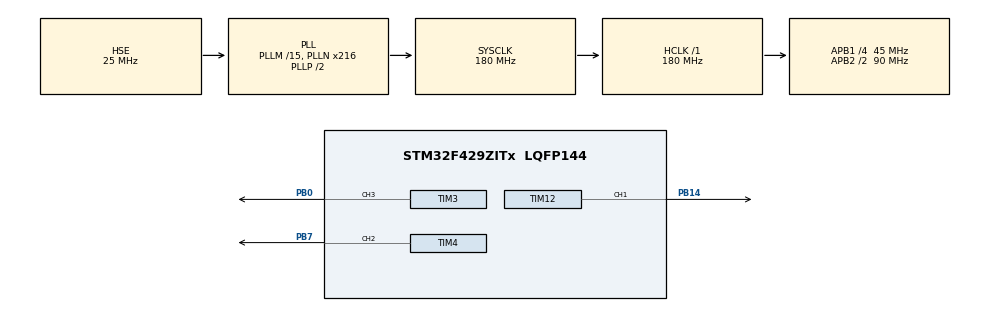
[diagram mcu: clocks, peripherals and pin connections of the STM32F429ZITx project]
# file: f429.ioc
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Mcu.Family=STM32F4
Mcu.Name=STM32F429ZITx
Mcu.Package=LQFP144
NVIC.PriorityGroup=NVIC_PRIORITYGROUP_4
NVIC.TIM4_IRQn=true\:0\:0\:false\:false\:true\:true\:true\:true
NVIC.TIM8_BRK_TIM12_IRQn=true\:0\:0\:false\:false\:true\:true\:true\:true
PA13.Mode=Serial_Wire
PA13.Signal=SYS_JTMS-SWDIO
PA14.Mode=Serial_Wire
PA14.Signal=SYS_JTCK-SWCLK
PB0.Signal=S_TIM3_CH3
PB14.Signal=S_TIM12_CH1
PB7.Signal=S_TIM4_CH2
PH0/OSC_IN.Mode=HSE-External-Oscillator
PH0/OSC_IN.Signal=RCC_OSC_IN
PH1/OSC_OUT.Mode=HSE-External-Oscillator
PH1/OSC_OUT.Signal=RCC_OSC_OUT
ProjectManager.HeapSize=0x200
ProjectManager.StackSize=0x400
ProjectManager.TargetToolchain=STM32CubeIDE
RCC.48MHZClocksFreq_Value=90000000
RCC.AHBFreq_Value=180000000
RCC.APB1CLKDivider=RCC_HCLK_DIV4
RCC.APB1Freq_Value=45000000
RCC.APB1TimFreq_Value=90000000
RCC.APB2CLKDivider=RCC_HCLK_DIV2
RCC.APB2Freq_Value=90000000
RCC.APB2TimFreq_Value=180000000
RCC.CortexFreq_Value=180000000
RCC.HCLKFreq_Value=180000000
RCC.HSE_VALUE=25000000
RCC.HSI_VALUE=16000000
RCC.LSE_VALUE=32768
RCC.PLLM=15
RCC.PLLN=216
RCC.PLLSourceVirtual=RCC_PLLSOURCE_HSE
RCC.SYSCLKFreq_VALUE=180000000
RCC.SYSCLKSource=RCC_SYSCLKSOURCE_PLLCLK
RCC.VCOOutputFreq_Value=360000000
SH.S_TIM12_CH1.0=TIM12_CH1,PWM Generation1 CH1
SH.S_TIM3_CH3.0=TIM3_CH3,PWM Generation3 CH3
SH.S_TIM4_CH2.0=TIM4_CH2,PWM Generation2 CH2
TIM12.Channel-PWM\ Generation1\ CH1=TIM_CHANNEL_1
TIM12.Period=60000
TIM12.Pulse-PWM\ Generation1\ CH1=30000
TIM3.Channel-PWM\ Generation3\ CH3=TIM_CHANNEL_3
TIM3.Period=60000
TIM3.Pulse-PWM\ Generation3\ CH3=30000
TIM4.Channel-PWM\ Generation2\ CH2=TIM_CHANNEL_2
TIM4.Period=60000
TIM4.Pulse-PWM\ Generation2\ CH2=30000
board=custom

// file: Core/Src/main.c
/* USER CODE BEGIN Header */
/**
  ******************************************************************************
  * @file           : main.c
  * @brief          : Main program body
  ******************************************************************************
  * @attention
  *
  * Copyright (c) 2022 STMicroelectronics.
  * All rights reserved.
  *
  * This software is licensed under terms that can be found in the LICENSE file
  * in the root directory of this software component.
  * If no LICENSE file comes with this software, it is provided AS-IS.
  *
  ******************************************************************************
  */
/* USER CODE END Header */
#include "main.h"

 TIM_HandleTypeDef htim3;
TIM_HandleTypeDef htim4;
TIM_HandleTypeDef htim12;

void SystemClock_Config(void);
static void MX_GPIO_Init(void);
static void MX_TIM4_Init(void);
static void MX_TIM12_Init(void);
static void MX_TIM3_Init(void);

int main(void)
{

  /* MCU Configuration--------------------------------------------------------*/

  /* Reset of all peripherals, Initializes the Flash interface and the Systick. */
  HAL_Init();

  /* Configure the system clock */
  SystemClock_Config();

  /* Initialize all configured peripherals */
  MX_GPIO_Init();
  MX_TIM4_Init();
  MX_TIM12_Init();
  MX_TIM3_Init();
  /* USER CODE BEGIN 2 */
  HAL_TIM_PWM_Start_IT(&htim4, TIM_CHANNEL_2);
  HAL_TIM_PWM_Start_IT(&htim12, TIM_CHANNEL_1);
  HAL_TIM_PWM_Start_IT(&htim3, TIM_CHANNEL_3);
  uint16_t i = 0;
    volatile uint16_t j = 0;

  /* USER CODE END 2 */

  /* Infinite loop */
  /* USER CODE BEGIN WHILE */
  while (1)
  {
	  for(i = 0; i <= 60000; i++)
	            {
		  __HAL_TIM_SET_COMPARE(&htim4, TIM_CHANNEL_2, i);
	                    for(j = 0; j < 100; j++) __NOP();
	            }

	            HAL_Delay(200);

	            for(i = 60000; i > 0; i--)
	            {
	            	__HAL_TIM_SET_COMPARE(&htim4, TIM_CHANNEL_2, i);
	                    for(j = 0; j < 100; j++) __NOP();
	            }

	            HAL_Delay(200);

	            for(i = 0; i <= 60000; i++)
	            	            {
	            		  __HAL_TIM_SET_COMPARE(&htim12, TIM_CHANNEL_1, i);
	            	                    for(j = 0; j < 100; j++) __NOP();
	            	            }

	            	            HAL_Delay(200);

	            	            for(i = 60000; i > 0; i--)
	            	            {
	            	            	__HAL_TIM_SET_COMPARE(&htim12, TIM_CHANNEL_1, i);
	            	                    for(j = 0; j < 100; j++) __NOP();
	            	            }

	            	            HAL_Delay(200);

	            	            for(i = 0; i <= 60000; i++)
	            	            	            {
	            	            		  __HAL_TIM_SET_COMPARE(&htim3, TIM_CHANNEL_3, i);
	            	            	                    for(j = 0; j < 100; j++) __NOP();
	            	            	            }

	            	            	            HAL_Delay(200);

	            	            	            for(i = 60000; i > 0; i--)
	            	            	            {
	            	            	            	__HAL_TIM_SET_COMPARE(&htim3, TIM_CHANNEL_3, i);
	            	            	                    for(j = 0; j < 100; j++) __NOP();
	            	            	            }

	            	            	            HAL_Delay(200);

    /* USER CODE END WHILE */

  }
}

void SystemClock_Config(void)
{
  RCC_OscInitTypeDef RCC_OscInitStruct = {0};
  RCC_ClkInitTypeDef RCC_ClkInitStruct = {0};

  /** Configure the main internal regulator output voltage
  */
  __HAL_RCC_PWR_CLK_ENABLE();
  __HAL_PWR_VOLTAGESCALING_CONFIG(PWR_REGULATOR_VOLTAGE_SCALE1);

  /** Initializes the RCC Oscillators according to the specified parameters
  * in the RCC_OscInitTypeDef structure.
  */
  RCC_OscInitStruct.OscillatorType = RCC_OSCILLATORTYPE_HSE;
  RCC_OscInitStruct.HSEState = RCC_HSE_ON;
  RCC_OscInitStruct.PLL.PLLState = RCC_PLL_ON;
  RCC_OscInitStruct.PLL.PLLSource = RCC_PLLSOURCE_HSE;
  RCC_OscInitStruct.PLL.PLLM = 15;
  RCC_OscInitStruct.PLL.PLLN = 216;
  RCC_OscInitStruct.PLL.PLLP = RCC_PLLP_DIV2;
  RCC_OscInitStruct.PLL.PLLQ = 4;
  if (HAL_RCC_OscConfig(&RCC_OscInitStruct) != HAL_OK)
  {
    Error_Handler();
  }

  /** Activate the Over-Drive mode
  */
  if (HAL_PWREx_EnableOverDrive() != HAL_OK)
  {
    Error_Handler();
  }

  /** Initializes the CPU, AHB and APB buses clocks
  */
  RCC_ClkInitStruct.ClockType = RCC_CLOCKTYPE_HCLK|RCC_CLOCKTYPE_SYSCLK
                              |RCC_CLOCKTYPE_PCLK1|RCC_CLOCKTYPE_PCLK2;
  RCC_ClkInitStruct.SYSCLKSource = RCC_SYSCLKSOURCE_PLLCLK;
  RCC_ClkInitStruct.AHBCLKDivider = RCC_SYSCLK_DIV1;
  RCC_ClkInitStruct.APB1CLKDivider = RCC_HCLK_DIV4;
  RCC_ClkInitStruct.APB2CLKDivider = RCC_HCLK_DIV2;

  if (HAL_RCC_ClockConfig(&RCC_ClkInitStruct, FLASH_LATENCY_5) != HAL_OK)
  {
    Error_Handler();
  }
}

static void MX_TIM3_Init(void)
{

  TIM_MasterConfigTypeDef sMasterConfig = {0};
  TIM_OC_InitTypeDef sConfigOC = {0};

  htim3.Instance = TIM3;
  htim3.Init.Prescaler = 0;
  htim3.Init.CounterMode = TIM_COUNTERMODE_UP;
  htim3.Init.Period = 60000;
  htim3.Init.ClockDivision = TIM_CLOCKDIVISION_DIV1;
  htim3.Init.AutoReloadPreload = TIM_AUTORELOAD_PRELOAD_DISABLE;
  if (HAL_TIM_PWM_Init(&htim3) != HAL_OK)
  {
    Error_Handler();
  }
  sMasterConfig.MasterOutputTrigger = TIM_TRGO_RESET;
  sMasterConfig.MasterSlaveMode = TIM_MASTERSLAVEMODE_DISABLE;
  if (HAL_TIMEx_MasterConfigSynchronization(&htim3, &sMasterConfig) != HAL_OK)
  {
    Error_Handler();
  }
  sConfigOC.OCMode = TIM_OCMODE_PWM1;
  sConfigOC.Pulse = 30000;
  sConfigOC.OCPolarity = TIM_OCPOLARITY_HIGH;
  sConfigOC.OCFastMode = TIM_OCFAST_DISABLE;
  if (HAL_TIM_PWM_ConfigChannel(&htim3, &sConfigOC, TIM_CHANNEL_3) != HAL_OK)
  {
    Error_Handler();
  }
  HAL_TIM_MspPostInit(&htim3);

}

static void MX_TIM4_Init(void)
{

  TIM_MasterConfigTypeDef sMasterConfig = {0};
  TIM_OC_InitTypeDef sConfigOC = {0};

  htim4.Instance = TIM4;
  htim4.Init.Prescaler = 0;
  htim4.Init.CounterMode = TIM_COUNTERMODE_UP;
  htim4.Init.Period = 60000;
  htim4.Init.ClockDivision = TIM_CLOCKDIVISION_DIV1;
  htim4.Init.AutoReloadPreload = TIM_AUTORELOAD_PRELOAD_DISABLE;
  if (HAL_TIM_PWM_Init(&htim4) != HAL_OK)
  {
    Error_Handler();
  }
  sMasterConfig.MasterOutputTrigger = TIM_TRGO_RESET;
  sMasterConfig.MasterSlaveMode = TIM_MASTERSLAVEMODE_DISABLE;
  if (HAL_TIMEx_MasterConfigSynchronization(&htim4, &sMasterConfig) != HAL_OK)
  {
    Error_Handler();
  }
  sConfigOC.OCMode = TIM_OCMODE_PWM1;
  sConfigOC.Pulse = 30000;
  sConfigOC.OCPolarity = TIM_OCPOLARITY_HIGH;
  sConfigOC.OCFastMode = TIM_OCFAST_DISABLE;
  if (HAL_TIM_PWM_ConfigChannel(&htim4, &sConfigOC, TIM_CHANNEL_2) != HAL_OK)
  {
    Error_Handler();
  }
  HAL_TIM_MspPostInit(&htim4);

}

static void MX_TIM12_Init(void)
{

  TIM_OC_InitTypeDef sConfigOC = {0};

  htim12.Instance = TIM12;
  htim12.Init.Prescaler = 0;
  htim12.Init.CounterMode = TIM_COUNTERMODE_UP;
  htim12.Init.Period = 60000;
  htim12.Init.ClockDivision = TIM_CLOCKDIVISION_DIV1;
  htim12.Init.AutoReloadPreload = TIM_AUTORELOAD_PRELOAD_DISABLE;
  if (HAL_TIM_PWM_Init(&htim12) != HAL_OK)
  {
    Error_Handler();
  }
  sConfigOC.OCMode = TIM_OCMODE_PWM1;
  sConfigOC.Pulse = 30000;
  sConfigOC.OCPolarity = TIM_OCPOLARITY_HIGH;
  sConfigOC.OCFastMode = TIM_OCFAST_DISABLE;
  if (HAL_TIM_PWM_ConfigChannel(&htim12, &sConfigOC, TIM_CHANNEL_1) != HAL_OK)
  {
    Error_Handler();
  }
  HAL_TIM_MspPostInit(&htim12);

}

static void MX_GPIO_Init(void)
{

  /* GPIO Ports Clock Enable */
  __HAL_RCC_GPIOH_CLK_ENABLE();
  __HAL_RCC_GPIOB_CLK_ENABLE();
  __HAL_RCC_GPIOA_CLK_ENABLE();

}

void Error_Handler(void)
{
  __disable_irq();
  while (1)
  {
  }
}
